# nrf52 register map
Vendor: Nordic Semiconductor; Series: nrf52; File version: 1
CPU: CM4 r0p1, little endian, MPU, FPU, 3 interrupt priority bits
Registers are 32-bit, read-write, reset 0x0 unless marked. A register's access mark holds for its fields unless they carry their own. Offsets are from the block's base; [hi:lo] are bit positions; lines under a group give offsets from that group; 'fields as' and 'values as' point back to an identical list.

## SPI0 — Serial Peripheral Interface 0
Base 0x40003000; alternate view of SPIM0
Same registers: SPI1 0x40004000 (alternate view of SPIM1), SPI2 0x40023000 (alternate view of SPIM2)
0x108 EVENTS_READY — TXD byte sent and RXD byte received
0x304 INTENSET — Enable interrupt
  [2] READY — Write '1' to Enable interrupt for READY event
    on read: 0=Disabled (Read: Disabled); 1=Enabled (Read: Enabled) | on write: 1=Set (Enable)
0x308 INTENCLR — Disable interrupt
  [2] READY — Write '1' to Disable interrupt for READY event
    on read: 0=Disabled (Read: Disabled); 1=Enabled (Read: Enabled) | on write: 1=Clear (Disable)
0x500 ENABLE — Enable SPI
  [3:0] ENABLE — Enable or disable SPI
    0=Disabled (Disable SPI); 1=Enabled (Enable SPI)
0x508 PSEL group — Unspecified
  0x00 SCK reset 0xFFFFFFFF — Pin select for SCK
    [31:0] PSELSCK — Pin number configuration for SPI SCK signal
      0xFFFFFFFF=Disconnected
  0x04 MOSI reset 0xFFFFFFFF — Pin select for MOSI
    [31:0] PSELMOSI — Pin number configuration for SPI MOSI signal
      0xFFFFFFFF=Disconnected
  0x08 MISO reset 0xFFFFFFFF — Pin select for MISO
    [31:0] PSELMISO — Pin number configuration for SPI MISO signal
      0xFFFFFFFF=Disconnected
0x518 RXD ro read-has-side-effects
  [7:0] RXD — RX data received. Double buffered
0x51C TXD
  [7:0] TXD — TX data to send. Double buffered
0x524 FREQUENCY reset 0x4000000 — SPI frequency
  [31:0] FREQUENCY — SPI master data rate
    0x2000000=K125 (125 kbps); 0x4000000=K250 (250 kbps); 0x8000000=K500 (500 kbps); 0x10000000=M1 (1 Mbps); 0x20000000=M2 (2 Mbps); 0x40000000=M4 (4 Mbps); 0x80000000=M8 (8 Mbps)
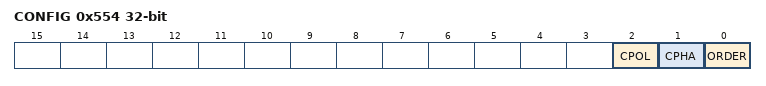
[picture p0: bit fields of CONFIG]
0x554 CONFIG — Configuration register
  [2] CPOL — Serial clock (SCK) polarity
    0=ActiveHigh; 1=ActiveLow
  [1] CPHA — Serial clock (SCK) phase
    0=Leading (Sample on leading edge of clock, shift serial data on trailing edge); 1=Trailing (Sample on trailing edge of clock, shift serial data on leading edge)
  [0] ORDER — Bit order
    0=MsbFirst (Most significant bit shifted out first); 1=LsbFirst (Least significant bit shifted out first)

## TWI0 — I2C compatible Two-Wire Interface 0
Base 0x40003000; alternate view of SPIM0
Same registers: TWI1 0x40004000 (alternate view of SPIM1)
0x00 TASKS_STARTRX wo — Start TWI receive sequence
0x08 TASKS_STARTTX wo — Start TWI transmit sequence
0x14 TASKS_STOP wo — Stop TWI transaction
0x1C TASKS_SUSPEND wo — Suspend TWI transaction
0x20 TASKS_RESUME wo — Resume TWI transaction
0x104 EVENTS_STOPPED — TWI stopped
0x108 EVENTS_RXDREADY — TWI RXD byte received
0x11C EVENTS_TXDSENT — TWI TXD byte sent
0x124 EVENTS_ERROR — TWI error
0x138 EVENTS_BB — TWI byte boundary, generated before each byte that is sent or received
0x148 EVENTS_SUSPENDED — TWI entered the suspended state
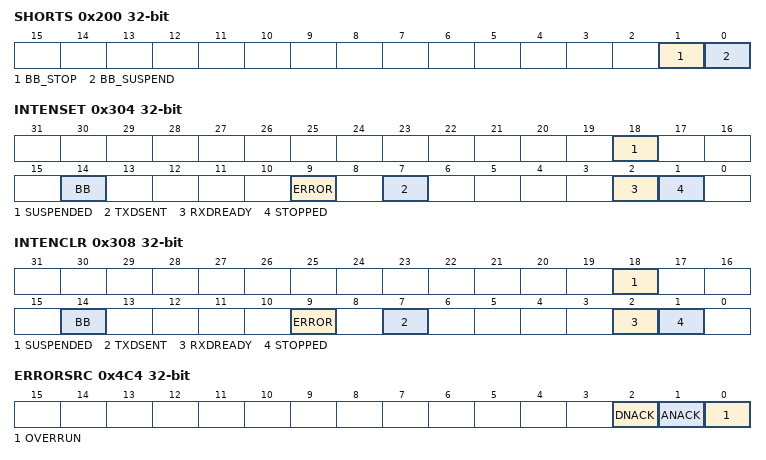
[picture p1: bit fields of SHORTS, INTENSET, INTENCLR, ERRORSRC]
0x200 SHORTS — Shortcut register
  [1] BB_STOP — Shortcut between BB event and STOP task
    0=Disabled (Disable shortcut); 1=Enabled (Enable shortcut)
  [0] BB_SUSPEND — Shortcut between BB event and SUSPEND task
    0=Disabled (Disable shortcut); 1=Enabled (Enable shortcut)
0x304 INTENSET — Enable interrupt
  [all] fields
    on read: 0=Disabled (Read: Disabled); 1=Enabled (Read: Enabled) | on write: 1=Set (Enable)
  [18] SUSPENDED — Write '1' to Enable interrupt for SUSPENDED event
  [14] BB — Write '1' to Enable interrupt for BB event
  [9] ERROR — Write '1' to Enable interrupt for ERROR event
  [7] TXDSENT — Write '1' to Enable interrupt for TXDSENT event
  [2] RXDREADY — Write '1' to Enable interrupt for RXDREADY event
  [1] STOPPED — Write '1' to Enable interrupt for STOPPED event
0x308 INTENCLR — Disable interrupt
  [all] fields
    on read: 0=Disabled (Read: Disabled); 1=Enabled (Read: Enabled) | on write: 1=Clear (Disable)
  [18] SUSPENDED — Write '1' to Disable interrupt for SUSPENDED event
  [14] BB — Write '1' to Disable interrupt for BB event
  [9] ERROR — Write '1' to Disable interrupt for ERROR event
  [7] TXDSENT — Write '1' to Disable interrupt for TXDSENT event
  [2] RXDREADY — Write '1' to Disable interrupt for RXDREADY event
  [1] STOPPED — Write '1' to Disable interrupt for STOPPED event
0x4C4 ERRORSRC write-1-clears — Error source
  [2] DNACK — NACK received after sending a data byte (write '1' to clear)
    on read: 0=NotPresent (Read: error not present); 1=Present (Read: error present) | on write: 1=Clear (Write: clear error on writing '1')
  [1] ANACK — NACK received after sending the address (write '1' to clear)
    values as DNACK
  [0] OVERRUN — Overrun error
    on read: 0=NotPresent (Read: no overrun occurred); 1=Present (Read: overrun occurred) | on write: 1=Clear (Write: clear error on writing '1')
0x500 ENABLE — Enable TWI
  [3:0] ENABLE — Enable or disable TWI
    0=Disabled (Disable TWI); 5=Enabled (Enable TWI)
0x508 PSELSCL reset 0xFFFFFFFF — Pin select for SCL
  [31:0] PSELSCL — Pin number configuration for TWI SCL signal
    0xFFFFFFFF=Disconnected
0x50C PSELSDA reset 0xFFFFFFFF — Pin select for SDA
  [31:0] PSELSDA — Pin number configuration for TWI SDA signal
    0xFFFFFFFF=Disconnected
0x518 RXD ro read-has-side-effects
  [7:0] RXD
0x51C TXD
  [7:0] TXD
0x524 FREQUENCY reset 0x4000000 — TWI frequency
  [31:0] FREQUENCY — TWI master clock frequency
    0x1980000=K100 (100 kbps); 0x4000000=K250 (250 kbps); 0x6680000=K400 (400 kbps (actual rate 410.256 kbps))
0x588 ADDRESS — Address used in the TWI transfer
  [6:0] ADDRESS

## Notices in the file
Copyright (c) 2010 - 2018, Nordic Semiconductor ASA All rights reserved.
Redistribution and use in source and binary forms, with or without
modification, are permitted provided that the following conditions are met:
1. Redistributions of source code must retain the above copyright notice, this
list of conditions and the following disclaimer.
2. Redistributions in binary form must reproduce the above copyright
notice, this list of conditions and the following disclaimer in the
documentation and/or other materials provided with the distribution.
3. Neither the name of Nordic Semiconductor ASA nor the names of its
contributors may be used to endorse or promote products derived from this
software without specific prior written permission.
THIS SOFTWARE IS PROVIDED BY THE COPYRIGHT HOLDERS AND CONTRIBUTORS "AS IS"
AND ANY EXPRESS OR IMPLIED WARRANTIES, INCLUDING, BUT NOT LIMITED TO, THE
IMPLIED WARRANTIES OF MERCHANTABILITY, AND FITNESS FOR A PARTICULAR PURPOSE
ARE DISCLAIMED. IN NO EVENT SHALL NORDIC SEMICONDUCTOR ASA OR CONTRIBUTORS BE
LIABLE FOR ANY DIRECT, INDIRECT, INCIDENTAL, SPECIAL, EXEMPLARY, OR
CONSEQUENTIAL DAMAGES (INCLUDING, BUT NOT LIMITED TO, PROCUREMENT OF
SUBSTITUTE GOODS OR SERVICES; LOSS OF USE, DATA, OR PROFITS; OR BUSINESS
INTERRUPTION) HOWEVER CAUSED AND ON ANY THEORY OF LIABILITY, WHETHER IN
CONTRACT, STRICT LIABILITY, OR TORT (INCLUDING NEGLIGENCE OR OTHERWISE)
ARISING IN ANY WAY OUT OF THE USE OF THIS SOFTWARE, EVEN IF ADVISED OF THE
POSSIBILITY OF SUCH DAMAGE.
